VERSION ""

NS_ :

BS_:
BU_:
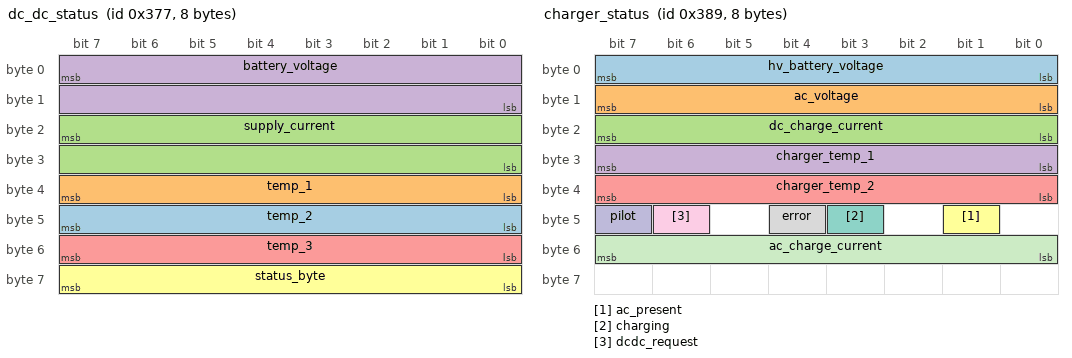
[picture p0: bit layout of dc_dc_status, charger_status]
BO_ 887 dc_dc_status: 8 Vector__XXX
   SG_ temp_2 : 47|8@0+ (1,-40) [-40|215] "deg" Vector__XXX
   SG_ temp_1 : 39|8@0+ (1,-40) [-40|215] "deg" Vector__XXX
   SG_ supply_current : 23|16@0+ (0.1,0) [0|6553.5] "A" Vector__XXX
   SG_ battery_voltage : 7|16@0+ (0.01,0) [0|655.35] "V" Vector__XXX
   SG_ temp_3 : 55|8@0+ (1,-40) [-40|215] "deg" Vector__XXX
   SG_ status_byte : 63|8@0+ (1,0) [0|0] "" Vector__XXX

BO_ 905 charger_status: 8 Vector__XXX
   SG_ hv_battery_voltage : 7|8@0+ (2,0) [0|510] "" Vector__XXX
   SG_ ac_voltage : 15|8@0+ (1,0) [0|255] "V" Vector__XXX
   SG_ dc_charge_current : 23|8@0+ (0.1,0) [0|255] "A" Vector__XXX
   SG_ charger_temp_1 : 31|8@0+ (1,-40) [-40|215] "degC" Vector__XXX
   SG_ charger_temp_2 : 39|8@0+ (1,-40) [-40|215] "degC" Vector__XXX
   SG_ ac_present : 41|1@0+ (1,0) [0|0] "" Vector__XXX
   SG_ charging : 43|1@0+ (1,0) [0|0] "" Vector__XXX
   SG_ error : 44|1@0+ (1,0) [0|0] "" Vector__XXX
   SG_ dcdc_request : 46|1@0+ (1,0) [0|0] "" Vector__XXX
   SG_ pilot : 47|1@0+ (1,0) [0|0] "" Vector__XXX
   SG_ ac_charge_current : 48|8@1+ (0.1,0) [0|0] "" Vector__XXX

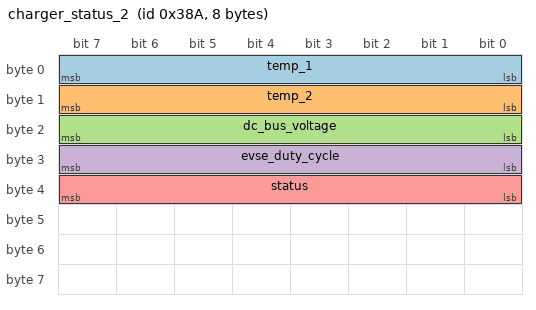
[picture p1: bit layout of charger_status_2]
BO_ 906 charger_status_2: 8 Vector__XXX
   SG_ temp_1 : 7|8@0+ (1,-45) [-45|220] "degC" Vector__XXX
   SG_ temp_2 : 15|8@0+ (1,-40) [-40|215] "degC" Vector__XXX
   SG_ dc_bus_voltage : 23|8@0+ (2,0) [0|510] "V" Vector__XXX
   SG_ evse_duty_cycle : 31|8@0+ (1,0) [0|255] "%" Vector__XXX
   SG_ status : 39|8@0+ (1,0) [0|0] "" Vector__XXX

BO_ 646 charging_request: 8 Vector__XXX
   SG_ requested_voltage : 7|16@0+ (0.1,0) [0|0] "volts" Vector__XXX
   SG_ requested_current : 16|8@1+ (0.1,0) [0|0] "amps" Vector__XXX

BO_ 645 EVSE_control: 8 Vector__XXX
   SG_ Control : 16|8@1+ (1,0) [0|0] "" Vector__XXX

BA_DEF_ BO_ "GenMsgBackgroundColor" STRING ;
BA_DEF_ BO_ "GenMsgForegroundColor" STRING ;
BA_DEF_DEF_ "GenMsgBackgroundColor" "#ffffff";
BA_DEF_DEF_ "GenMsgForegroundColor" "#000000";
CM_ BO_ 646 "These are sent to the Charger to control the current, the voltage appears to be ignored.";
VAL_ 887 status_byte 32 "Standby" 33 "Error" 34 "Operation";
VAL_ 905 ac_present 0 "No_AC_present" 1 "AC_Live";
VAL_ 905 charging 0 "Standby" 1 "Charging" 0 "";
VAL_ 905 error 1 "Error_(no_CAN_messages_received)" 0 "No_errors";
VAL_ 905 dcdc_request 1 "DC-DC_convertor_request_active" 0 "DC-DC_inactive";
VAL_ 905 pilot 1 "1khz_pilot_present" 0 "No_pilot";
VAL_ 906 status 0 "Ready" 4 "Wait_for_mains_voltage" 8 "Ready_for_charging" 0 "No_input";
VAL_ 645 Control 182 "Pull_in_EVSE";
